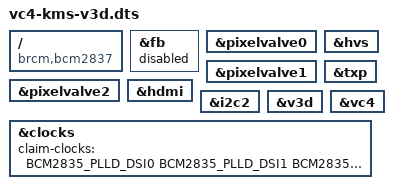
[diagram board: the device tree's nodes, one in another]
/*
 * https://github.com/raspberrypi/linux/blob/rpi-6.12.y/arch/arm/boot/dts/overlays/vc4-kms-v3d-overlay.dts
*/

/dts-v1/;
/plugin/;

#include <dt-bindings/clock/bcm2835.h>

/ {
	compatible = "brcm,bcm2837";

	fragment@0 {
		target = <&fb>;
		__overlay__ {
			status = "disabled";
		};
	};

	fragment@1 {
		target = <&pixelvalve0>;
		__overlay__ {
			status = "okay";
		};
	};

	fragment@2 {
		target = <&pixelvalve1>;
		__overlay__ {
			status = "okay";
		};
	};

	fragment@3 {
		target = <&pixelvalve2>;
		__overlay__ {
			status = "okay";
		};
	};

	fragment@4 {
		target = <&hvs>;
		__overlay__ {
			status = "okay";
		};
	};

	fragment@5 {
		target = <&txp>;
		__overlay__ {
			status = "okay";
		};
	};

	fragment@6 {
		target = <&hdmi>;
		__overlay__ {
			status = "okay";
		};
	};

	fragment@7 {
		target = <&i2c2>;
		__overlay__ {
			status = "okay";
		};
	};

	fragment@8 {
		target = <&v3d>;
		__overlay__ {
			status = "okay";
		};
	};

	fragment@9 {
		target = <&vc4>;
		__overlay__ {
			status = "okay";
		};
	};

	fragment@10 {
		target = <&clocks>;
		__overlay__ {
			claim-clocks = <
				BCM2835_PLLD_DSI0
				BCM2835_PLLD_DSI1
				BCM2835_PLLH_AUX
				BCM2835_PLLH_PIX
			>;
		};
	};
};
